# MIMXRT1024 register map
Vendor: nxp.com; File version: 1.0
CPU: CM7 r0p1, little endian, MPU, FPU, VTOR, 4 interrupt priority bits
Registers are 32-bit, read-write, reset 0x0 unless marked. A register's access mark holds for its fields unless they carry their own. Offsets are from the block's base; [hi:lo] are bit positions.

## EWM
Base 0x400B4000
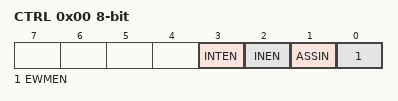
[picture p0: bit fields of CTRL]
0x00 CTRL 8-bit — Control Register
  [3] INTEN — Interrupt Enable.
    0=ZERO (Deasserts the interrupt request.); 1=INT_REQ (Generates an interrupt request, when EWM_OUT_b is asserted.)
  [2] INEN rw-once — Input Enable.
    0=DISABLE (EWM_in port is disabled.); 1=ENABLE (EWM_in port is enabled.)
  [1] ASSIN rw-once — EWM_in's Assertion State Select.
    0=DISABLE (Default assert state of the EWM_in signal.); 1=ENABLE (Inverts the assert state of EWM_in signal.)
  [0] EWMEN rw-once — EWM enable.
    0=DISABLE (EWM module is disabled.); 1=ENABLE (EWM module is enabled.)
0x01 SERV 8-bit — Service Register
  [7:0] SERVICE
0x02 CMPL 8-bit rw-once — Compare Low Register
  [7:0] COMPAREL
0x03 CMPH 8-bit rw-once reset 0xFF — Compare High Register
  [7:0] COMPAREH
0x04 CLKCTRL 8-bit rw-once — Clock Control Register
  [1:0] CLKSEL
0x05 CLKPRESCALER 8-bit rw-once — Clock Prescaler Register
  [7:0] CLK_DIV

## WDOG1 — WDOG
Base 0x400B8000
Same registers: WDOG2 0x400D0000
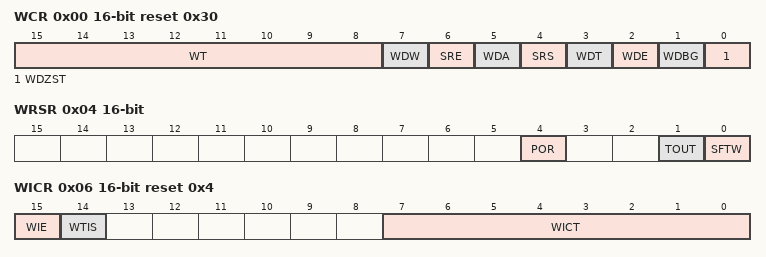
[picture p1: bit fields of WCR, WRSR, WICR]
0x00 WCR 16-bit reset 0x30 — Watchdog Control Register
  [15:8] WT
    0=- 0.5 Seconds (Default); 1=- 1.0 Seconds; 2=- 1.5 Seconds; 3=- 2.0 Seconds; 255=- 128 Seconds
  [7] WDW
    0=Continue WDOG timer operation (Default); 1=Suspend WDOG timer operation
  [6] SRE — software reset extension, an option way to generate software reset
    0=using original way to generate software reset (default); 1=using new way to generate software reset
  [5] WDA
    0=Assert WDOG_B output; 1=No effect on system (Default)
  [4] SRS
    0=Assert system reset signal; 1=No effect on the system (Default)
  [3] WDT
    0=No effect on WDOG_B (Default); 1=Assert WDOG_B upon a Watchdog Time-out event
  [2] WDE
    0=Disable the Watchdog (Default); 1=Enable the Watchdog
  [1] WDBG
    0=Continue WDOG timer operation (Default); 1=Suspend the watchdog timer
  [0] WDZST
    0=Continue timer operation (Default); 1=Suspend the watchdog timer
0x02 WSR 16-bit — Watchdog Service Register
  [15:0] WSR
    0x5555=Write to the Watchdog Service Register (WDOG_WSR); 0xAAAA=Write to the Watchdog Service Register (WDOG_WSR)
0x04 WRSR 16-bit ro — Watchdog Reset Status Register
  [4] POR
    0=Reset is not the result of a power on reset; 1=Reset is the result of a power on reset
  [1] TOUT
    0=Reset is not the result of a WDOG timeout; 1=Reset is the result of a WDOG timeout
  [0] SFTW
    0=Reset is not the result of a software reset; 1=Reset is the result of a software reset
0x06 WICR 16-bit reset 0x4 — Watchdog Interrupt Control Register
  [15] WIE
    0=Disable Interrupt (Default); 1=Enable Interrupt
  [14] WTIS write-1-clears
    0=No interrupt has occurred (Default); 1=Interrupt has occurred
  [7:0] WICT
    0=WICT[7:0] = Time duration between interrupt and time-out is 0 seconds; 1=WICT[7:0] = Time duration between interrupt and time-out is 0.5 seconds; 4=WICT[7:0] = Time duration between interrupt and time-out is 2 seconds (Default); 255=WICT[7:0] = Time duration between interrupt and time-out is 127.5 seconds
0x08 WMCR 16-bit reset 0x1 — Watchdog Miscellaneous Control Register
  [0] PDE
    0=Power Down Counter of WDOG is disabled; 1=Power Down Counter of WDOG is enabled (Default)

## RTWDOG — WDOG
Base 0x400BC000
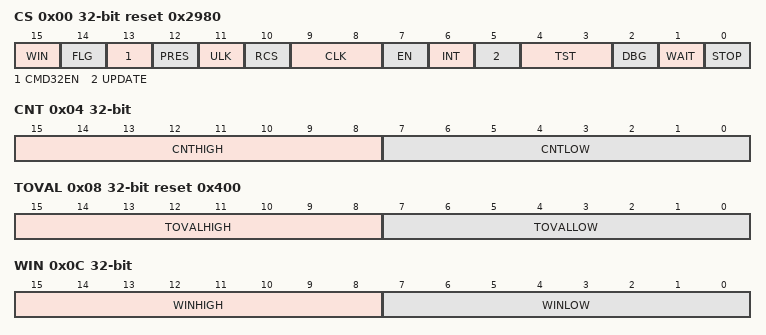
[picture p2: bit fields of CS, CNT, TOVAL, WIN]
0x00 CS reset 0x2980 — Watchdog Control and Status Register
  [15] WIN — Watchdog Window
    0=Window mode disabled; 1=Window mode enabled
  [14] FLG write-1-clears — Watchdog Interrupt Flag
    0=No interrupt occurred; 1=An interrupt occurred
  [13] CMD32EN — Enables or disables WDOG support for 32-bit (otherwise 16-bit or 8-bit) refresh/unlock command write words
    0=Disables support for 32-bit refresh/unlock command write words. Only 16-bit or 8-bit is supported.; 1=Enables support for 32-bit refresh/unlock command write words. 16-bit or 8-bit is NOT supported.
  [12] PRES — Watchdog prescaler
    0=256 prescaler disabled; 1=256 prescaler enabled
  [11] ULK ro — Unlock status
    0=WDOG is locked; 1=WDOG is unlocked
  [10] RCS ro — Reconfiguration Success
    0=Reconfiguring WDOG; 1=Reconfiguration is successful
  [9:8] CLK — Watchdog Clock
  [7] EN — Watchdog Enable
    0=Watchdog disabled; 1=Watchdog enabled
  [6] INT — Watchdog Interrupt
    0=Watchdog interrupts are disabled. Watchdog resets are not delayed.; 1=Watchdog interrupts are enabled. Watchdog resets are delayed by 128 bus clocks from the interrupt vector fetch.
  [5] UPDATE — Allow updates
    0=Updates not allowed. After the initial configuration, the watchdog cannot be later modified without forcing a reset.; 1=Updates allowed. Software can modify the watchdog configuration registers within 128 bus clocks after performing the unlock write sequence.
  [4:3] TST — Watchdog Test
    0=Watchdog test mode disabled; 1=Watchdog user mode enabled. (Watchdog test mode disabled.) After testing the watchdog, software should use this setting to indicate that the watchdog is functioning normally in user mode.; 2=Watchdog test mode enabled, only the low byte is used. CNT[CNTLOW] is compared with TOVAL[TOVALLOW].; 3=Watchdog test mode enabled, only the high byte is used. CNT[CNTHIGH] is compared with TOVAL[TOVALHIGH].
  [2] DBG — Debug Enable
    0=Watchdog disabled in chip debug mode; 1=Watchdog enabled in chip debug mode
  [1] WAIT — Wait Enable
    0=Watchdog disabled in chip wait mode; 1=Watchdog enabled in chip wait mode
  [0] STOP — Stop Enable
    0=Watchdog disabled in chip stop mode; 1=Watchdog enabled in chip stop mode
0x04 CNT — Watchdog Counter Register
  [15:8] CNTHIGH — High byte of the Watchdog Counter
  [7:0] CNTLOW — Low byte of the Watchdog Counter
0x08 TOVAL reset 0x400 — Watchdog Timeout Value Register
  [15:8] TOVALHIGH — High byte of the timeout value
  [7:0] TOVALLOW — Low byte of the timeout value
0x0C WIN — Watchdog Window Register
  [15:8] WINHIGH — High byte of Watchdog Window
  [7:0] WINLOW — Low byte of Watchdog Window

## Notices in the file
Copyright 2016-2022 NXP
All rights reserved.
SPDX-License-Identifier: BSD-3-Clause
